# DSS0_VID register map
Vendor: Texas Instruments
Peripheral module from a debugger description file (folder am65x).
Registers are 32-bit, access per field, reset 0x0 unless marked. A register's access mark holds for its fields unless they carry their own. Offsets are as the file gives them; lines under a group give offsets from that group; [hi:lo] are bit positions; {n}, {i} and the like mark numbered series; 'fields as' and 'values as' point back to an identical list; <NAME> marks a mode.

## DSS0_VID
0x00 DSS0_VID_ACCUH_0 — The register configures the resize accumulator init values for horizontal up/down-sampling of the video window. VIDx_ACCU__0 & VIDx_ACCU__1 for ping-pong mechanism with external trigger, based on the field polarity. This register is used for ARGB and Y in YUV420/YUV422. Shadow register
  [23:0] HORIZONTALACCU rw — Horizontal initialization accu signed value
0x04 DSS0_VID_ACCUH_1 — The register configures the resize accumulator init values for horizontal up/down-sampling of the video window. VIDx_ACCU__0 & VIDx_ACCU__1 for ping-pong mechanism with external trigger, based on the field polarity. This register is used for ARGB and Y in YUV420/YUV422. Shadow register
  fields as DSS0_VID_ACCUH_0
0x08 DSS0_VID_ACCUH2_0 — The register configures the resize accumulator init value for horizontal up/down-sampling of the video window. VID n_ACCU2__0 & VID n_ACCU2__1 for ping-pong mechanism with external trigger, based on the field polarity. This register is used for U/V components in YUV420/YUV422. It is not used when the input format is any RGB format. Shadow register
  fields as DSS0_VID_ACCUH_0
0x0C DSS0_VID_ACCUH2_1 — The register configures the resize accumulator init value for horizontal up/down-sampling of the video window. VID n_ACCU2__0 & VID n_ACCU2__1 for ping-pong mechanism with external trigger, based on the field polarity. This register is used for U/V components in YUV420/YUV422. It is not used when the input format is any RGB format. Shadow register
  fields as DSS0_VID_ACCUH_0
0x10 DSS0_VID_ACCUV_0 — The register configures the resize accumulator init values for horizontal and vertical up/down-sampling of the video window. VIDx_ACCU__0 & VIDx_ACCU__1 for ping-pong mechanism with external trigger, based on the field polarity. It is used for ARGB and Y in YUV420/YUV422. Shadow register
  [23:0] VERTICALACCU rw — Vertical initialization accu signed value
0x14 DSS0_VID_ACCUV_1 — The register configures the resize accumulator init values for horizontal and vertical up/down-sampling of the video window. VIDx_ACCU__0 & VIDx_ACCU__1 for ping-pong mechanism with external trigger, based on the field polarity. It is used for ARGB and Y in YUV420/YUV422. Shadow register
  [23:0] VERTICALACCU rw — Vertical initialization accu signed value
0x18 DSS0_VID_ACCUV2_0 — The register configures the resize accumulator init value for vertical up/down-sampling of the video window. ACCU2__0 & ACCU2__1 for ping-pong mechanism with external trigger, based on the field polarity. It is used for U/V components for YUV420. It is not used when the input format is any RGB format or YUV422. Shadow register
  [23:0] VERTICALACCU rw — Vertical initialization accu signed value
0x1C DSS0_VID_ACCUV2_1 — The register configures the resize accumulator init value for vertical up/down-sampling of the video window. ACCU2__0 & ACCU2__1 for ping-pong mechanism with external trigger, based on the field polarity. It is used for U/V components for YUV420. It is not used when the input format is any RGB format or YUV422. Shadow register
  [23:0] VERTICALACCU rw — Vertical initialization accu signed value
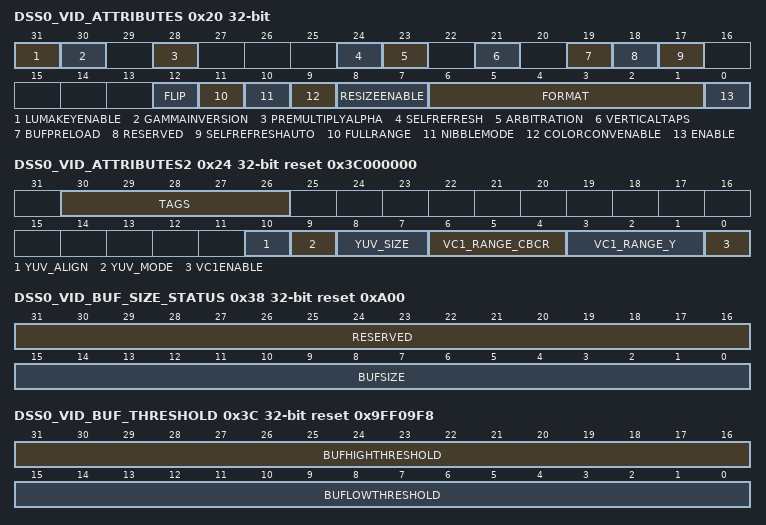
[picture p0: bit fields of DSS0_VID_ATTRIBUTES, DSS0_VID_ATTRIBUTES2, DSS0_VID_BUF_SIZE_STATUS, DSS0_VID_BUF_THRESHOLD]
0x20 DSS0_VID_ATTRIBUTES — The register configures the VID_ATTRIBUTES of the video window. Shadow register
  [31] LUMAKEYENABLE rw — Enable Luma Key transparency matching 0h = Luma Key operation is disabled 1h = Luma Key operation is enabled
  [30] GAMMAINVERSION rw — Inverse Gamma support [using the CLUT table] 0h = Gamma inversion is disabled 1h = Gamma inversion is enabled
  [28] PREMULTIPLYALPHA rw — The field configures the DISPC VID to process incoming data as premultiplied alpha data or non premultiplied alpha data. Default setting is non premultiplied alpha data 0h = Non premultiplyalpha data color component 1h = Premultiplyalpha data color component
  [24] SELFREFRESH rw — Enables the self refresh of the video window, from its own DMA buffer only 0h = The video pipeline accesses the interconnect to fetch data from the system memory 1h = The video pipeline does not need any more to fetch data from memory. Only the DMA buffer associated with the video1 is used. It takes effect after the frame has been loaded in the DMA buffer
  [23] ARBITRATION rw — Determines the priority of the video pipeline. The video pipeline is one of the high priority pipelines. The arbitration gives always the priority first to the high priority pipelines using round-robin between them. When there are only normal priority pipelines sending requests, the round-robin applies between the normal priority pipelines 0h = The video pipeline is one of the normal priority pipelines 1h = The video pipeline is one of the high priority pipelines
  [21] VERTICALTAPS rw — This register field is functional only for VID pipeline. It is not functional for VIDL1 pipeline. Video Vertical Resize Tap Number. The vertical poly-phase filter can be configured in 3-tap or 5-tap configuration. According to the number of taps, the maximum input picture width is double while using 3-tap compared to 5-tap 0h = 3 taps are used for the vertical filtering logic. The 2 other taps are not used. The associated bit-fields for the 2 other taps coefficients do not need to be initialized 1h = 5 taps are used for the vertical filtering logic
  [19] BUFPRELOAD rw — Video Preload Value 0h = H/W prefetches pixels up to the 1h = H/W prefetches pixels up to high threshold value
  [18] RESERVED ro — Write 0's for future compatibility. Reads return 0
  [17] SELFREFRESHAUTO rw — Automatic self refresh mode 0h = The transition from SELFREFRESH disabled to enabled is controlled SW 1h = The transition from SELFREFRESH disabled to enabled is controlled only by HW
  [12] FLIP rw — Describes the frame buffer flip operation 0h = No Flip 1h = Frame Buffer is flipped
  [11] FULLRANGE rw — Color Space Conversion full range setting 0h = Limited Range Selected 1h = Full Range Selected
  [10] NIBBLEMODE rw — Video Nibble mode [only for 1-, 2-, and 4-bpp]0h = Nibble Mode Disabled 1h = Nibble Mode Enabled
  [9] COLORCONVENABLE rw — Enable the color space conversion. The HW does not enable/disable the conversion based on the pixel format 0h = Color Space Conversion Disabled 1h = Color Space Conversion Enabled
  [8:7] RESIZEENABLE rw — This register field is functional only for VID pipeline. It is not functional for VIDL1 pipeline. Video Resize Enable 0h = Disable both horizontal and vertical resizing 1h = Enable horizontal resizing 2h = Enable vertical resizing 3h = Enable both horizontal and vertical resizing
  [6:1] FORMAT rw — Video Format. It defines the pixel format when fetching the video frame buffer. (Alpha-X) denotes that Alpha can be disabled and can be replaced with global alpha value. 00h = ARGB16-4444 01h = ABGR16-4444 02h = RGBA16-4444 03h = RGB16-565 04h = BGR16-565 05h = ARGB16-1555 06h = ABGR16-1555 07h = ARGB32-8888 08h = ABGR32-8888 09h = RGBA32-8888 0Ah = BGRA32-8888 0Bh = RGB24-888 0Ch = BGR24-888 0Eh = ARGB32-2101010 0Fh = ABGR32-2101010 10h = ARGB64-16161616 11h = RGBA64-16161616 12h = BITMAP1 13h = BITMAP2 14h = BITMAP4 15h = BITMAP8 16h = RGB565A8 17h = BGR565A8 20h = ARGB16-4444 (Alpha-X) 21h = ABGR16-4444 (Alpha-X) 22h = RGBA16-4444 (Alpha-X) 25h = ARGB16-1555 (Alpha-X) 26h = ABGR16-1555 (Alpha-X) 27h = ARGB32-8888 (Alpha-X) 28h = ABGR32-8888 (Alpha-X) 29h = RGBA32-8888 (Alpha-X) 2Ah = BGRA32-8888 (Alpha-X) 2Eh = ARGB32-2101010 (Alpha-X) 2Fh = ABGR32-2101010 (Alpha-X) 30h = ARGB64-16161616 (Alpha-X) 31h = RGBA64-16161616 (Alpha-X) 3Dh = YUV420-NV12 (planar) 3Eh = YUV422-YUV2 (packed) 3Fh = YUV422-UYVY (packed)
  [0] ENABLE rw — Video pipeline Enable 0h = Video Pipe Disabled 1h = Video Pipe Enabled
0x24 DSS0_VID_ATTRIBUTES2 reset 0x3C000000 — The register configures the of the video window. Shadow register
  [30:26] TAGS rw — Number of OCP TAGS to be used for the pipeline [from 0x0 to 0xF]. A value of 0x0 means only a single tag will be used. A value of 0xF means all 16 tags can be used
  [10] YUV_ALIGN rw — Alignment [MSB or LSB align] for unpacked 10b/12b YUV data 0h = lsb aligned - unused msb 1h = msb aligned - unused lsb
  [9] YUV_MODE rw — Mode of packing for YUV data [only for 10b/12b formats] 0h = YUV 10-bit formats have the same component packing order as 8-bit formats except that the packing is done across a multiple 32-bit word with 2 MSB in each 32-bit word not used. YUV 12-bit formats have the same component packing order as 8-bit formats except that the packing is done across a multiple 64-bit word with 4 MSB in each 64-bit word not used 1h = YUV 10-bit/12-bit unpacked formats have the same component packing order as 8-bit formats except that each component is stored in a 16-bit container - with MSB or LSB bits within the 16-bit container not used depending on the MSB/LSB alignment
  [8:7] YUV_SIZE rw — Size of YUV data 8b/10b/12b 0h = 8b per component-default 1h = 10b per component 2h = 12b per component
  [6:4] VC1_RANGE_CBCR rw — Defines the VC1 range value for the CbCr component from 0 to 7
  [3:1] VC1_RANGE_Y rw — Defines the VC1 range value for the Y component from 0 to 7
  [0] VC1ENABLE rw — Enable/disable the VC1 range mapping processing. The bit-field is ignored if the format is not one of the supported YUV formats 0h = VC1 range mapping disabled 1h = VC1 range mapping enabled
0x28 DSS0_VID_BA_0 rw — The register configures the base address of the single video buffer. In case of single plane ARGB or YUV, this is the BA. In case of two plane YUV, this is the BA_Y. In case of two plane RGB565-A8, this is the BA_Alpha. BA__0 & BA__1 for ping-pong mechanism with external trigger, based on the field polarity otherwise only BA__0 is used. Shadow register
  [31:0] BA — Video base address. Base address of the video buffer [Aligned on pixel DSS0_VID_SIZE boundary except for the following. In case of RGB24 packed format, 4-pixel alignment is required. In case of YUV422, 2-pixel alignment is required. In case of YUV420, byte alignment is required]
0x2C DSS0_VID_BA_1 rw — The register configures the base address of the single video buffer. In case of single plane ARGB or YUV, this is the BA. In case of two plane YUV, this is the BA_Y. In case of two plane RGB565-A8, this is the BA_Alpha. BA__0 & BA__1 for ping-pong mechanism with external trigger, based on the field polarity otherwise only BA__0 is used. Shadow register
  fields as DSS0_VID_BA_0
0x30 DSS0_VID_BA_UV_0 rw — The register configures the base address of the UV buffer for two plane YUV or RGB buffer for two plane RGB565-A8, for the video window. BA_UV__0 & BA_UV__1 for ping-pong mechanism with external trigger, based on the field polarity otherwise only BA_UV__0 is used. Shadow register
  [31:0] BA — Video base address aligned on 16-bit boundary. Base address of the UV video buffer used only in case of YUV420-NV12.
0x34 DSS0_VID_BA_UV_1 rw — The register configures the base address of the UV buffer for two plane YUV or RGB buffer for two plane RGB565-A8, for the video window. BA_UV__0 & BA_UV__1 for ping-pong mechanism with external trigger, based on the field polarity otherwise only BA_UV__0 is used. Shadow register
  fields as DSS0_VID_BA_UV_0
0x38 DSS0_VID_BUF_SIZE_STATUS ro reset 0xA00 — The register returns the Video buffer for the video pipeline
  [31:16] RESERVED — Write 0's for future compatibility Reads return 0
  [15:0] BUFSIZE — Video DMA buffer Size in number of 128-bits
0x3C DSS0_VID_BUF_THRESHOLD rw reset 0x9FF09F8 — The register configures the video buffer associated with the video pipeline. Shadow register
  [31:16] BUFHIGHTHRESHOLD — DMA buffer High Threshold. Number of 128-bits defining the threshold value
  [15:0] BUFLOWTHRESHOLD — DMA buffer Low Threshold. Number of 128-bits defining the threshold value
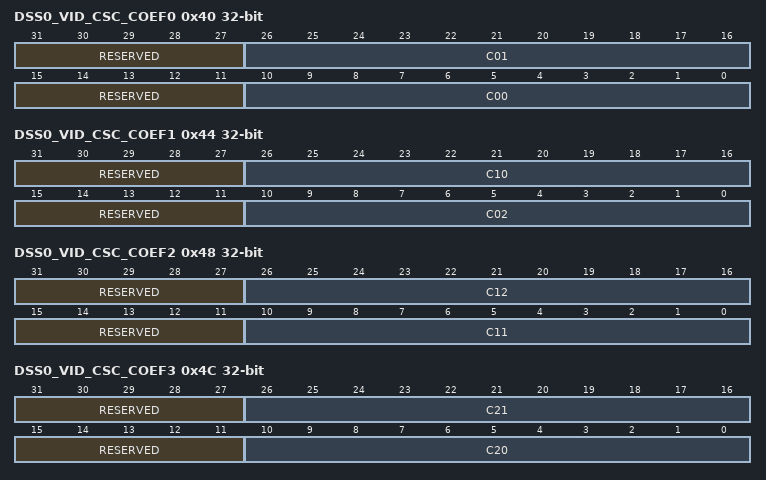
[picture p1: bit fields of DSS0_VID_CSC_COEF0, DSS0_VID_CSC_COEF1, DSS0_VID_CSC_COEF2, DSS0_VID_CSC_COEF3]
0x40 DSS0_VID_CSC_COEF0 — The register configures the color space conversion matrix coefficients. Shadow register
  [31:27] RESERVED ro — Write 0's for future compatibility Reads return 0
  [26:16] C01 rw — C01 Coefficient. Encoded signed value [from -1024 to 1023]
  [15:11] RESERVED ro — Write 0's for future compatibility Reads return 0
  [10:0] C00 rw — C00 Coefficient. Encoded signed value [from -1024 to 1023]
0x44 DSS0_VID_CSC_COEF1 — The register configures the color space conversion matrix coefficients. Shadow register
  [31:27] RESERVED ro — Write 0's for future compatibility Reads return 0
  [26:16] C10 rw — C10 Coefficient. Encoded signed value [from -1024 to 1023]
  [15:11] RESERVED ro — Write 0's for future compatibility Reads return 0
  [10:0] C02 rw — C02 Coefficient. Encoded signed value [from -1024 to 1023]
0x48 DSS0_VID_CSC_COEF2 — The register configures the color space conversion matrix coefficients. Shadow register
  [31:27] RESERVED ro — Write 0's for future compatibility Reads return 0
  [26:16] C12 rw — C12 Coefficient. Encoded signed value [from -1024 to 1023]
  [15:11] RESERVED ro — Write 0's for future compatibility Reads return 0
  [10:0] C11 rw — C11 Coefficient. Encoded signed value [from -1024 to 1023]
0x4C DSS0_VID_CSC_COEF3 — The register configures the color space conversion matrix coefficients. Shadow register
  [31:27] RESERVED ro — Write 0's for future compatibility Reads return 0
  [26:16] C21 rw — C21 coefficient. Encoded signed value [from -1024 to 1023]
  [15:11] RESERVED ro — Write 0's for future compatibility Reads return 0
  [10:0] C20 rw — C20 coefficient. Encoded signed value [from -1024 to 1023]
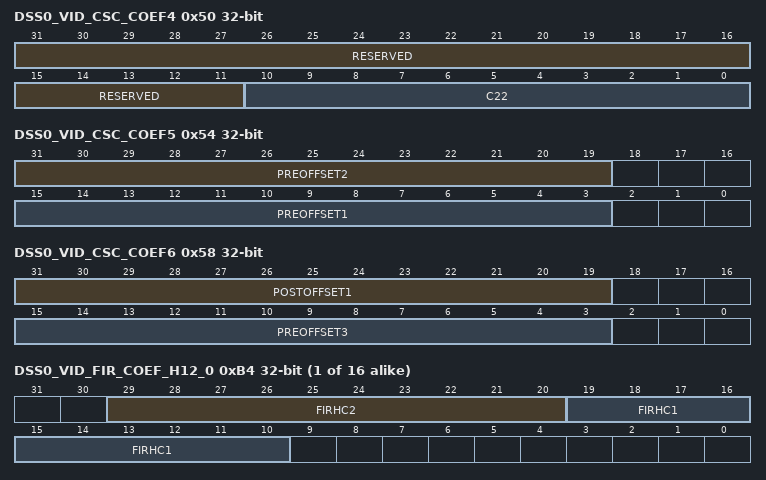
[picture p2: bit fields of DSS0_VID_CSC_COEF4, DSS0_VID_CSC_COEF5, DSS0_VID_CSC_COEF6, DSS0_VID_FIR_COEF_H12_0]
0x50 DSS0_VID_CSC_COEF4 — The register configures the color space conversion matrix coefficients. Shadow register
  [31:11] RESERVED ro — Write 0's for future compatibility Reads return 0
  [10:0] C22 rw — C22 Coefficient. Encoded signed value [from -1024 to 1023]
0x54 DSS0_VID_CSC_COEF5 — The register configures the color space conversion matrix coefficients. Shadow register
  [31:19] PREOFFSET2 rw — Row-2 pre-offset. Encoded signed value [from -4096 to 4095]
  [15:3] PREOFFSET1 rw — Row1 pre-offset. Encoded signed value [from -4096 to 4095]
0x58 DSS0_VID_CSC_COEF6 — The register configures the color space conversion matrix coefficients. Shadow register
  [31:19] POSTOFFSET1 rw — Row-1 post-offset. Encoded signed value [from -4096 to 4095]
  [15:3] PREOFFSET3 rw — Row-3 pre-offset. Encoded signed value [from -4096 to 4095]
0x5C DSS0_VID_FIRH reset 0x200000 — The register configures the resize factor for horizontal up/down-sampling of the video window. It is used for ARGB and Y setting. Shadow register
  [23:0] FIRHINC rw — Horizontal increment of the up/down-sampling filter. The value 0 is invalid
0x60 DSS0_VID_FIRH2 reset 0x200000 — The register configures the resize factor for horizontal up/down-sampling of the video window. It is used for U/V components for YUV 422 and 420 input formats. It is not used if input format is any RGB format. Shadow register
  [23:0] FIRHINC rw — Horizontal increment of the up/down-sampling filter for Cb and Cr. The value 0 is invalid
0x64 DSS0_VID_FIRV reset 0x200000 — The register configures the resize factor for vertical up/down-sampling of the video window. It is used for ARGB and Y setting. Shadow register
  [23:0] FIRVINC rw — Vertical increment of the up/down-sampling filter. The value 0 is invalid
0x68 DSS0_VID_FIRV2 reset 0x200000 — The register configures the resize factor for vertical up/down-sampling of the video window. It is used for U/V components for YUV420 input format. It is not used when the input format is any RGB format or YUV422 format. Shadow register.
  [23:0] FIRVINC rw — Vertical increment of the up/down-sampling filter for Cb and Cr. The value 0 is invalid
{0x6C+4i} DSS0_VID_FIR_COEF_H0_{i} (i=0..8) — The bank of registers configures the up/down-scaling coefficients for the horizontal resize of the video picture associated with the video window for the 16 phases. It is used for ARGB and Y setting. Shadow register
  [9:0] FIRHC0 rw — Unsigned coefficient C0 for the horizontal up/down-scaling with the phase {i}
{0x90+4i} DSS0_VID_FIR_COEF_H0_C_{i} (i=0..8) — The bank of registers configures the up/down-scaling coefficients for the horizontal resize of the video picture associated with the video window for the phases from 0 to 15. It is used for Crb and Cr setting. It is used only when the pixel format at the input of the filter is one of the YUV formats. When the register is not used by the HW, any value can be used for the bit-fields. Shadow register
  fields as DSS0_VID_FIR_COEF_H0_0
{0xB4+4i} DSS0_VID_FIR_COEF_H12_{i} (i=0..15) — The bank of registers configures the up/down-scaling coefficients for the horizontal resize of the video picture associated with the video window for the 16 phases. It is used for ARGB and Y setting. Shadow register
  [29:20] FIRHC2 rw — Signed coefficient C2 for the horizontal up/down-scaling with the phase {i}
  [19:10] FIRHC1 rw — Signed coefficient C1 for the horizontal up/down-scaling with the phase {i}
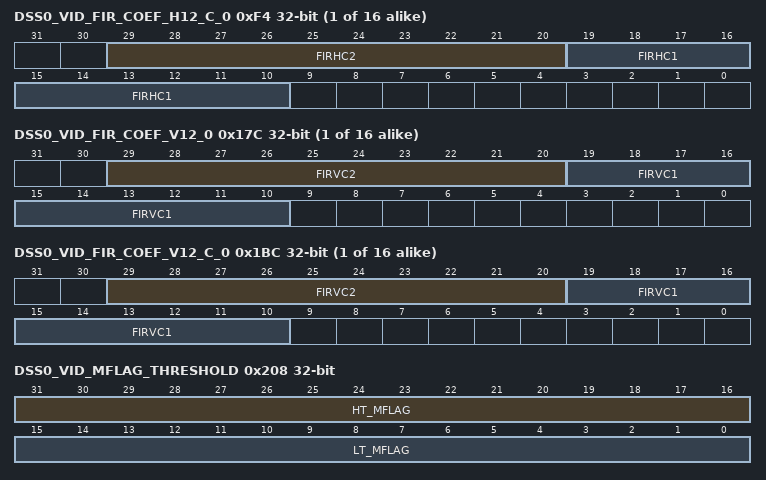
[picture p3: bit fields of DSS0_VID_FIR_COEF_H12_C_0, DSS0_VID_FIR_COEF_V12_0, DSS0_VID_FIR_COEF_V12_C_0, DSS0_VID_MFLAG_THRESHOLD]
{0xF4+4i} DSS0_VID_FIR_COEF_H12_C_{i} (i=0..15) — The bank of registers configures the up/down-scaling coefficients for the horizontal resize of the video picture associated with the video window for the phases from 0 to 15. It is used for Crb and Cr setting. It is used only when the pixel format at the input of the filter is one of the YUV formats. When the register is not used by the HW, any value can be used for the bit-fields. Shadow register
  fields as DSS0_VID_FIR_COEF_H12_0
{0x134+4i} DSS0_VID_FIR_COEF_V0_{i} (i=0..8) — The bank of registers configures the up/down-scaling coefficients for the vertical resize of the video picture associated with the video window for the 16 phases. It is used for ARGB and Y setting. Shadow register
  [9:0] FIRVC0 rw — Unsigned coefficient C0 for the vertical up/down-scaling with the phase {i}
{0x158+4i} DSS0_VID_FIR_COEF_V0_C_{i} (i=0..8) — The bank of registers configures the up/down-scaling coefficients for the vertical resize of the video picture associated with the video window for the phases from 0 to 15. It is used for Crb and Cr setting. It is used only when the pixel format at the input of the filter is one of the YUV formats. When the register is not used by the HW, any value can be used for the bit-fields. Shadow register
  fields as DSS0_VID_FIR_COEF_V0_0
{0x17C+4i} DSS0_VID_FIR_COEF_V12_{i} (i=0..15) — The bank of registers configures the up/down-scaling coefficients for the vertical resize of the video picture associated with the video window for the 16 phases. It is used for ARGB and Y setting. Shadow register
  [29:20] FIRVC2 rw — Signed coefficient C2 for the vertical up/down-scaling with the phase {i}
  [19:10] FIRVC1 rw — Signed coefficient C1 for the vertical up/down-scaling with the phase {i}
{0x1BC+4i} DSS0_VID_FIR_COEF_V12_C_{i} (i=0..15) — The bank of registers configures the up/down-scaling coefficients for the vertical resize of the video picture associated with the video window for the phases from 0 to 15. It is used for Crb and Cr setting. It is used only when the pixel format at the input of the filter is one of the YUV formats. When the register is not used by the HW, any value can be used for the bit-fields. Shadow register
  fields as DSS0_VID_FIR_COEF_V12_0
0x1FC DSS0_VID_GLOBAL_ALPHA reset 0xFF — The register defines the global alpha value for the video pipeline. Shadow register
  [7:0] GLOBALALPHA rw — Global alpha value from 0 to 255. 0 corresponds to fully transparent and 255 corresponds to fully opaque
0x208 DSS0_VID_MFLAG_THRESHOLD rw — Register
  [31:16] HT_MFLAG — MFlag High Threshold
  [15:0] LT_MFLAG — MFlag Low Threshold
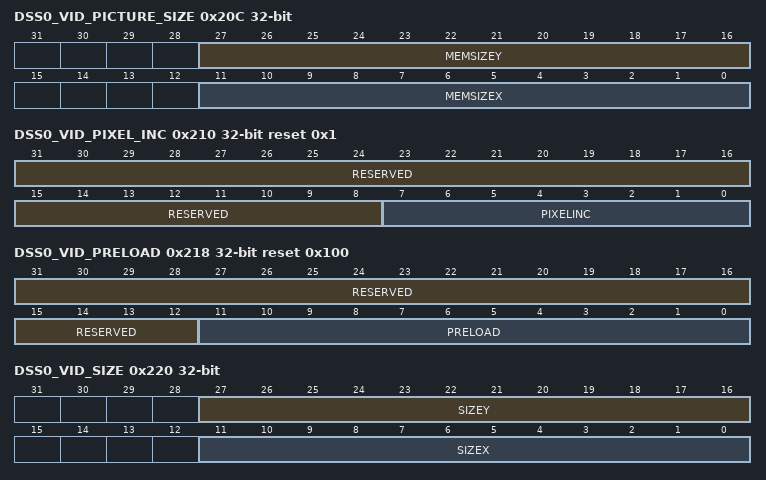
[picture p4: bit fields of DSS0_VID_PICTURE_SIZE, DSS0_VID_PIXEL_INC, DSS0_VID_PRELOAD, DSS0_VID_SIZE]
0x20C DSS0_VID_PICTURE_SIZE — The register configures the of the video picture associated with the video layer before up/down-scaling. Shadow register
  [27:16] MEMSIZEY rw — Number of lines of the video picture. Encoded value [from 1 to 4096] to specify the number of lines of the video picture in memory [program to value minus one]. When predecimation is set, the value represents the size of the image after predecimation, but the max size of the unpredecimated image size in memory is still bounded to 2exp[11].
  [11:0] MEMSIZEX rw — Number of pixels of the video picture. Encoded value [from 1 to 4096] to specify the number of pixels of the video picture in memory [program to value minus one]. The size is limited to the size of the line buffer of the vertical sampling block in case the video picture is processed by the vertical filtering unit [program to value minus one]. When predecimation is set, the value represents the size of the image after predecimation, but the max size of the unpredecimated image size in memory is still bounded to 2exp[11].
0x210 DSS0_VID_PIXEL_INC reset 0x1 — The register configures the number of bytes to increment between two pixels for the buffer associated with the video window. Shadow register
  [31:8] RESERVED ro — Write 0's for future compatibility Reads return 0
  [7:0] PIXELINC rw — Number of bytes to increment between two pixels. Encoded unsigned value [from 1 to 255] to specify the number of bytes between two pixels in the video buffer. The value 0 is invalid. The value 1 means next pixel. The value 1+n*bpp means increment of n pixels for YUV420. Max supported value is 128.
0x218 DSS0_VID_PRELOAD reset 0x100 — The register configures the DMA buffer of the video pipeline. Shadow register
  [31:12] RESERVED ro — Write 0's for future compatibility Reads return 0
  [11:0] PRELOAD rw — DMA buffer preload value. Number of 128-bit words defining the preload value.
0x21C DSS0_VID_ROW_INC rw reset 0x1 — The register configures the number of bytes to increment at the end of the row for the buffer associated with the video window. For YUV420 formats this corresponds to the Y Buffer. Shadow register
  [31:0] ROWINC — Number of bytes to increment at the end of the row. Encoded signed value [from -2-1 to 2] to specify the number of bytes to increment at the end of the row in the video buffer. The value 0 is invalid. The value 1 means next pixel. The value 1+n*bpp means increment of n pixels. The value 1- [n+1]*bpp means decrement of n pixels.
0x220 DSS0_VID_SIZE — The register configures the of the video window. Shadow register
  [27:16] SIZEY rw — Number of lines of the video window. Encoded value [from 1 to 4096] to specify the number of lines of the video window [program size-1].
  [11:0] SIZEX rw — Number of pixels of the video window. Encoded value [from 1 to 4096] to specify the number of pixels of the video window [program size-1].
0x22C DSS0_VID_BA_EXT_0 — The register configures the 16-bit base address extension. It is the base-address of the single video buffer for single plane ARGB or YUV. For the Y buffer for two plane YUV. For the Alpha buffer for two plane RGB565-A8. 0 & 1 : For ping-pong mechanism with external trigger, based on the field polarity. Shadow register.
  [15:0] BA_EXT rw — Video base address extension [16 bits]. Addr extension to make the address space 48b wide.
0x230 DSS0_VID_BA_EXT_1 — The register configures the 16-bit base address extension. It is the base-address of the single video buffer for single plane ARGB or YUV. For the Y buffer for two plane YUV. For the Alpha buffer for two plane RGB565-A8. 0 & 1 : For ping-pong mechanism with external trigger, based on the field polarity. Shadow register
  fields as DSS0_VID_BA_EXT_0
0x234 DSS0_VID_BA_UV_EXT_0 — The register configures the 16-bit base address extension of the UV buffer for two plane YUV or the RGB buffer for two plane RGB565-A8. 0 & 1 : For ping-pong mechanism with external trigger, based on the field polarity. Shadow register
  [15:0] BA_UV_EXT rw — Video base address extension [16 bits]. Addr extension to make the address space 48b wide.
0x238 DSS0_VID_BA_UV_EXT_1 — The register configures the 16-bit base address extension of the UV buffer for two plane YUV or the RGB buffer for two plane RGB565-A8. 0 & 1 : For ping-pong mechanism with external trigger, based on the field polarity. Shadow register
  fields as DSS0_VID_BA_UV_EXT_0
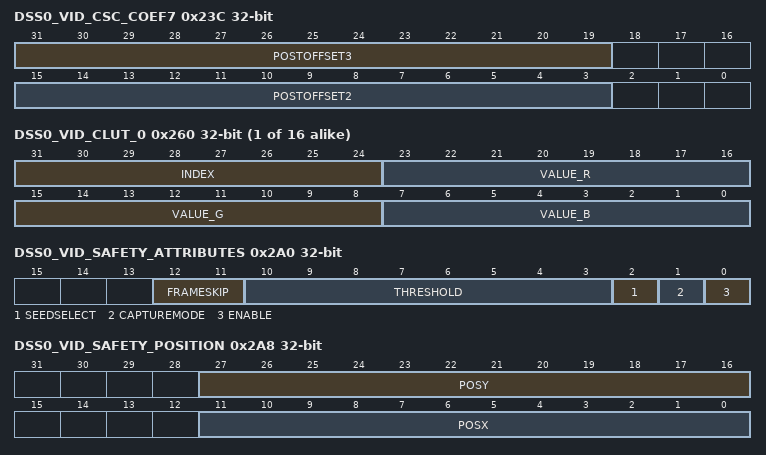
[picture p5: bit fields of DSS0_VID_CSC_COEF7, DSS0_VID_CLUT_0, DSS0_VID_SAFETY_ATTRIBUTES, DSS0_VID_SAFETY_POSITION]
0x23C DSS0_VID_CSC_COEF7 — The register configures the color space conversion matrix coefficients. Shadow register
  [31:19] POSTOFFSET3 rw — Row-3 post-offset. Encoded signed value [from -4096 to 4095].
  [15:3] POSTOFFSET2 rw — Row-2 post-offset. Encoded signed value [from -4096 to 4095].
0x248 DSS0_VID_ROW_INC_UV rw reset 0x1 — The register configures the number of bytes to increment at the end of the row for the UV buffer associated with the video window for YUV420 formats. For non-YUV420 formats this register is unused. Shadow register
  [31:0] ROWINC — Number of bytes to increment at the end of the row. Encoded signed value [from -2-1 to 2] to specify the number of bytes to increment at the end of the row in the video buffer. The value 0 is invalid. The value 1 means next pixel. The value 1+n*bpp means increment of n pixels. The value 1-[n+1]*bpp means decrement of n pixels.
{0x260+4i} DSS0_VID_CLUT_{i} wo (i=0..15) — The register configures the Color Look Up Table CLUT for VID pipeline. CLUT is used in conjunction with bitmap formats
  [31:24] INDEX — Defines the location in the table where the bit-fields VALUE_{R,G,B} is stored.
  [23:16] VALUE_R — 8-bit R-value to store at the location in the table defined by the bit-field INDEX.
  [15:8] VALUE_G — 8-bit G-value to store at the location in the table defined by the bit-field INDEX.
  [7:0] VALUE_B — 8-bit B-value to store at the location in the table defined by the bit-field INDEX.
0x2A0 DSS0_VID_SAFETY_ATTRIBUTES — The register configures the safety sub-region. Shadow register
  [12:11] FRAMESKIP rw — Indicates which frames to be skipped while doing FRAMEFREEZE or DATACHECK [Useful for interlaced displays].0h = No frames are skipped 1h = Even Frames are skipped starting from second frame after ENABLE 2h = Odd Frames are skipped starting from first frame after ENABLE 3h = Reserved
  [10:3] THRESHOLD rw — Allowed maximum number of frames with the same frame signature. When the freeze frame counter reaches 1 over this value [freeze_frame_thold+1], a freeze frame detection will occur. Note: The freeze frame counter is cleared on reset -OR- MISR not enabled -OR- terminal count reached -OR- compare == no match
  [2] SEEDSELECT rw — Initial seed selection control. 0h = Initial seed is always 0xFFFF_FFFF 1h = Initial seed is defined by SAFETY_LFSR_SEED.SEED
  [1] CAPTUREMODE rw — Mode of operation of the safety check module. 0h = Frame freeze detect enabled 1h = Data correctness check enabled
  [0] ENABLE rw — Safety check Enable for the region. Note: Transition from 0 to 1 clears the signature register
0x2A4 DSS0_VID_SAFETY_CAPT_SIGNATURE ro — The register captures the signature from the MISR of the safety sub-region. Shadow register
  [31:0] SIGNATURE — The register configures the reference signature of the safety sub-region. Shadow register
0x2A8 DSS0_VID_SAFETY_POSITION — The register configures the position of the safety sub-region. Shadow register
  [27:16] POSY rw — Y position of the safety sub-region. Encoded value [from 0 to 4095] to specify the Y position of the sub-region on the screen. The first line on the top of the screen has the Y-position 0
  [11:0] POSX rw — X position of the safety sub-region. Encoded value [from 0 to 4095] to specify the X position of the sub-region on the screen. The first pixel on the left of the screen has the X-position 0
0x2AC DSS0_VID_SAFETY_REF_SIGNATURE rw — The register configures the reference signature of the safety sub-region. Shadow register
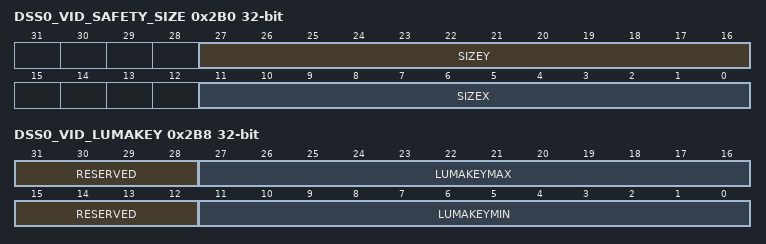
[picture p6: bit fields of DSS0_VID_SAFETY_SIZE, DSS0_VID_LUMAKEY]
0x2B0 DSS0_VID_SAFETY_SIZE — The register configures the of the safety sub-region. Shadow register
  [27:16] SIZEY rw — Height of the safety sub-region. Encoded value [from 0 to 4095] to specify the height of the sub-region on the screen. One line height region has value of 0
  [11:0] SIZEX rw — Width of the safety sub-region. Encoded value [from 0 to 4095] to specify the width of the sub-region on the screen. One pixel wide region has value of 0
0x2B4 DSS0_VID_SAFETY_LFSR_SEED rw — The register configures the seed [initial value] of the MISR. Otherwise, the MISR is initialized with 0xFFFF_FFFF. Shadow register
0x2B8 DSS0_VID_LUMAKEY — The register configures the LUMA KEY transparency min and max values. Shadow register
  [31:28] RESERVED ro — Write 0's for future compatibility. Reads return 0.
  [27:16] LUMAKEYMAX rw — 12b luma_key_max value
  [15:12] RESERVED ro — Write 0's for future compatibility. Reads return 0.
  [11:0] LUMAKEYMIN rw — 12b luma_key_min value
